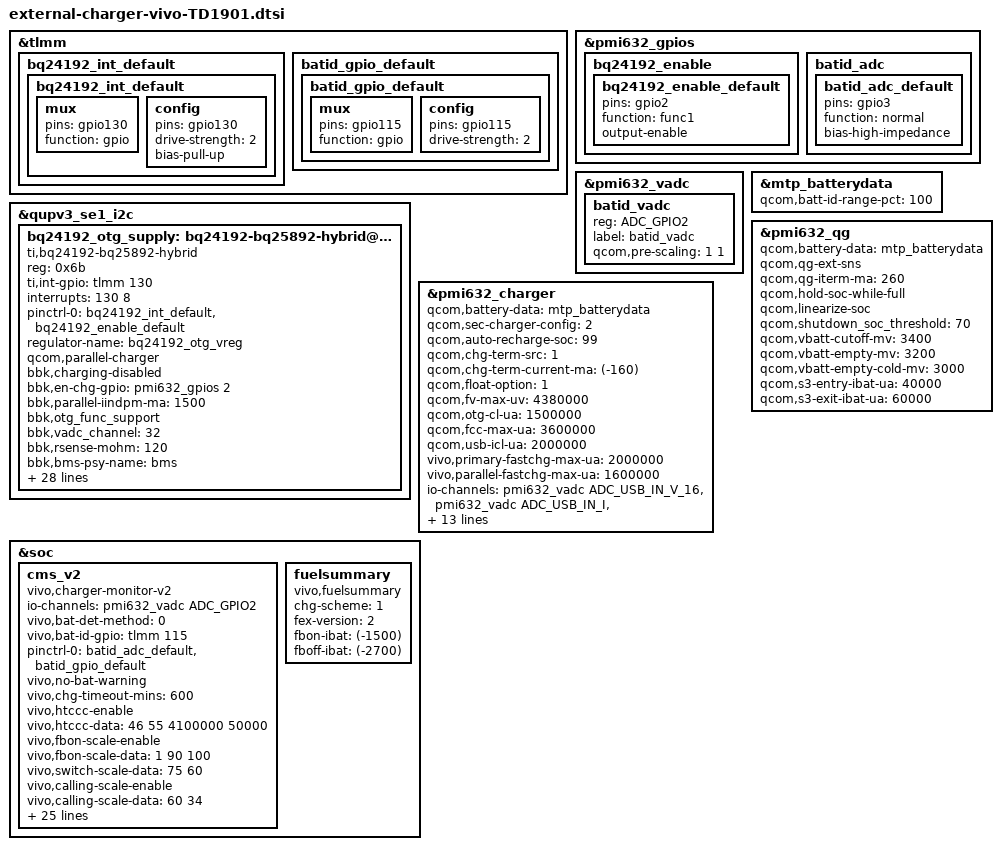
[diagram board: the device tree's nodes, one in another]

&tlmm {
	bq24192_int_default {
		bq24192_int_default: bq24192_int_default {
			mux {
				pins = "gpio130";
				function = "gpio";
			};
			config {
				pins = "gpio130";
				drive-strength = <2>;
				bias-pull-up;
			};
		};
	};
	batid_gpio_default {
		batid_gpio_default: batid_gpio_default {
			mux {
				pins = "gpio115";
				function = "gpio";
			};
			config {
				pins = "gpio115";
				drive-strength = <2>;
			};
		};
	};
};
&pmi632_gpios {
	bq24192_enable {
		bq24192_enable_default: bq24192_enable_default {
			pins = "gpio2";
			function = "func1";
			output-enable;
		};
	};
	batid_adc {
		batid_adc_default: batid_adc_default {
			pins = "gpio3";
			function = "normal";
			bias-high-impedance;
		};
	};
};
&pmi632_vadc {
	batid_vadc {
		reg = <ADC_GPIO2>;
		label = "batid_vadc";
		qcom,pre-scaling = <1 1>;
	};
};

&qupv3_se1_i2c {
	status = "ok";
		bq24192_otg_supply: bq24192-bq25892-hybrid@6b {
			compatible = "ti,bq24192-bq25892-hybrid";
			reg = <0x6b>;
			ti,int-gpio = <&tlmm 130 0x00>;
			interrupts = <130 8>;
			pinctrl-names = "default";
			pinctrl-0 = <&bq24192_int_default &bq24192_enable_default>;

			regulator-name = "bq24192_otg_vreg";

			/*config for bq24192*/
			qcom,parallel-charger;
			bbk,charging-disabled;
			bbk,en-chg-gpio = <&pmi632_gpios 2 0>;
			bbk,parallel-iindpm-ma = <1500>;
			bbk,otg_func_support;
			bbk,vadc_channel = <32>;
			bbk,rsense-mohm = <120>;
			bbk,bms-psy-name = "bms";
			bbk,secondary-chg-psy-name = "secondary_ac";
			ti,vbat-max-mv = <4400>;
			ti,chg-current-ma = <1500>;
			ti,pre-chg-current-ma = <200>;
			ti,term-current-ma = <128>;
			ti,sys-vimin-mv = <3500>;
			ti,vin-limit-mv = <4200>;
			ti,wlc-vin-limit-mv = <4100>;
			ti,step-dwn-current-ma = <100>;
			ti,cv-thr-mv = <4300>;
			ti,icl-vbus-mv = <4600>;
			ti,wlc-step-dwn-i-ma = <100>;
			ti,wlc-dwn-input-i-ma = <100>;
			ti,chg-tmout-mins = <600>;

			/*config for bq25892*/
			bbk,parallel-charger;
			//bbk,en-gpio = <&pmi8950_gpios 2 0>;
			ti,ircomp-mom = <0>;
			ti,vclamp-mv = <0>;
			ti,hvdcp-enable;
			ti,vindpm-5v-thr-mv = <4400>;
			ti,vindpm-9v-thr-mv = <7800>;
			ti,vindpm-offset-mv = <500>;
			ti,cfg-fastchg-current-ma = <2048>;
			ti,parallel-usb-min-current-ma = <1200>;
			ti,parallel-usb-9v-min-current-ma = <900>;
			ti,parallel-fastchg-current-max-ma = <1500>;
			ti,fastchg-current-max-ma = <1728>;
			ti,fastchg-accuracy = <5>;
			ti,use-absolute-vindpm;
		};
};

&mtp_batterydata {
	qcom,batt-id-range-pct = <100>;
	#include "qg-batterydata-TD1901-3700mah.dtsi"
};

&pmi632_qg {
	qcom,battery-data = <&mtp_batterydata>;
	qcom,qg-ext-sns;

	qcom,qg-iterm-ma = <260>;
	qcom,hold-soc-while-full;
	qcom,linearize-soc;
	qcom,shutdown_soc_threshold = <70>;

	qcom,vbatt-cutoff-mv = <3400>;
	qcom,vbatt-empty-mv = <3200>;
	qcom,vbatt-empty-cold-mv = <3000>;

	qcom,s3-entry-ibat-ua = <40000>;
	qcom,s3-exit-ibat-ua = <60000>;
};

&pmi632_charger {
	qcom,battery-data = <&mtp_batterydata>;
	qcom,sec-charger-config = <2>;
	qcom,auto-recharge-soc = <99>;
	qcom,chg-term-src = <1>;
	qcom,chg-term-current-ma = <(-160)>;
	qcom,float-option = <1>;
	qcom,fv-max-uv = <4380000>;
	qcom,otg-cl-ua = <1500000>;

	qcom,fcc-max-ua = <3600000>;
	qcom,usb-icl-ua = <2000000>;
	vivo,primary-fastchg-max-ua = <2000000>;
	vivo,parallel-fastchg-max-ua = <1600000>;

	/*primary board temp & parallel board temp*/
	io-channels = <&pmi632_vadc ADC_USB_IN_V_16>,
		      <&pmi632_vadc ADC_USB_IN_I>,
		      <&pmi632_vadc ADC_CHG_TEMP>,
		      <&pmi632_vadc ADC_DIE_TEMP>,
		      <&pm6125_vadc ADC_AMUX_THM2_PU2>,
		      <&pm6125_vadc ADC_AMUX_THM2_PU2>;
	io-channel-names = "usb_in_voltage",
			   "usb_in_current",
			   "chg_temp",
			   "die_temp",
			   "pri_ntc_temp",
			   "pl_ntc_temp";

	//vivo,usbsel-gpio = <&tlmm 104 0>;
	//vivo,usboe-gpio = <&tlmm 21 0>;

	vivo,soft-term-enable;
	vivo,soft-term-capacity-limit = <100>;
	vivo,soft-term-timer-limit = <30>;//5min

	vivo,tracking_soc_enable;
	vivo,tracking_step_second= <10>;

	/*charge condition force 5v*/
	vivo,cc-force-5v-soc-limit = <90>;

	/*
	enum SUPPORTED_ADAPTER {
		SUPPORTED_ADAPTER_DEFAULT = 0
		SUPPORTED_ADAPTER_VIVO_LV_DCHG__5V_4500MA = 1,
		SUPPORTED_ADAPTER_VIVO_HV_DCHG__10V_2250MA = 2,
		SUPPORTED_ADAPTER_QC20__9V_2000MA = 3,
	};
	*/
	vivo,supported-adapter = <3>;

	/*spec max and min current*/
	vivo,current-spec-min-ma = <2200>;
	vivo,current-spec-max-ma = <3800>;
};


&soc {
	cms_v2 {
		compatible = "vivo,charger-monitor-v2";

		//vivo,battery-plugable = <0>;//0:unplugable,1:plugable , default:0

		/* battery ID ADC */
		io-channels = <&pmi632_vadc ADC_GPIO2>;
		io-channel-names = "cms_batt_id";

		vivo,bat-det-method = <0>;  //r:0 , rc:1 , eprom:2, ex-fg:3
		vivo,bat-id-gpio = <&tlmm 115 0x00>;
		pinctrl-names = "default";
		pinctrl-0 = <&batid_adc_default &batid_gpio_default>;

		vivo,no-bat-warning;
		//vivo,no-chg-timeout;
		vivo,chg-timeout-mins = <600>;

		//high temperature charger current control enable
		vivo,htccc-enable;
		vivo,htccc-data = <46 55 4100000 50000>;

		vivo,fbon-scale-enable;
		vivo,fbon-scale-data = <1 90 100>;

		//vivo,switch-scale-enable;
		vivo,switch-scale-data = <75 60>;

		vivo,calling-scale-enable;
		vivo,calling-scale-data = <60 34>;

		//vivo,fixed-scale-enable;
		vivo,fixed-scale-data = <60 2000 1600>;

		//battery voltage compensate
		vivo,vbat-r-comp = <20>;

		/*data processing : batt-temp*/
		//vivo,dp-batt-temp-enable;
		vivo,dp-batt-temp-data = <100>;

		/* usb connecter protect param */
		//vivo,usb-connecter-protect-enable;
		vivo,usb-id-protect-data= <1100 1547 500>;/* 500K, 2M, fcc */
		vivo,usb-conn-heat-protect-data= <800 550>;

		//ibat scale base on temperature
		vivo,normal-tc-row-col = <7 5>;
		vivo,normal-tc-data = <550 8888 0 0 0>,	//1.5c
					<450 549 50 0 0>,
					<150 449 120 0 0>,
					<100 149 100 4200000 70>,
					<50 99 49 0 0>,//50->49
					<0 49 49 4200000 30>,//50->49
					<(-8888) (-1) 0 0 0>;

		//adjust fastchg base on board temperature and fb off
		//vivo,intell-charge-enable;
		vivo,parallel-temp-enable = <1 1>;//<x y> x:fb-on y:fb-off
		//fb-on param
		vivo,primary-fbon-tc-row-col = <5 3>;
		vivo,primary-fbon-tc-data = <501 8888 300>,
					    <451 500 450>,
					    <421 450 1000>,
					    <381 420 1350>,
					    <(-8888) 380 1600>;
		vivo,parallel-fbon-tc-row-col = <4 3>;
		vivo,parallel-fbon-tc-data = <451 8888 512>,
					     <441 450 640>,
					     <421 440 960>,
					     <(-8888) 420 1152>;
		//fb-off param
		vivo,primary-fboff-tc-row-col = <4 3>;
		vivo,primary-fboff-tc-data = <411 8888 900>,
					     <391 410 1500>,
					     <371 390 1650>,
					     <(-8888) 370 1950>;
		vivo,parallel-fboff-tc-row-col = <5 3>;
		vivo,parallel-fboff-tc-data = <411 8888 512>,
					      <385 410 576>,
					      <371 384 832>,
					      <361 370 1152>,
					      <(-8888) 360 1408>;
	};

	fuelsummary {
		compatible = "vivo,fuelsummary";

		/************************************************************
		 *
		 *  0	vivo-fastchg
		 *  1	qcom-dualchg
		 *  2	mtk-dualchg
		 *  3	qcom-normchg
		 *  4	mtk-normchg
		 *
		 ***********************************************************/
		chg-scheme = <1>;
		fex-version = <2>;
		fbon-ibat = <(-1500)>;
		fboff-ibat = <(-2700)>;
	};
};
